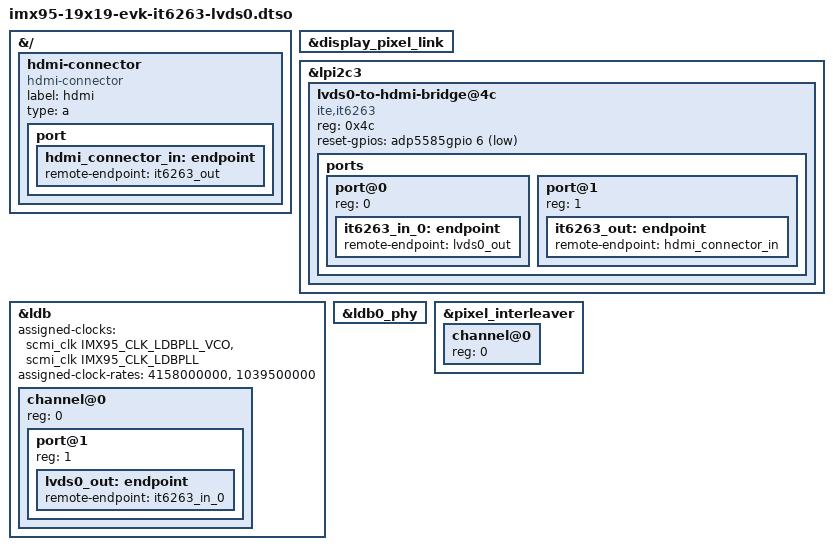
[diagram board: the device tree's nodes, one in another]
// SPDX-License-Identifier: (GPL-2.0+ OR MIT)
/*
 * Copyright 2023 NXP
 */

/dts-v1/;
/plugin/;

#include <dt-bindings/clock/fsl,imx95-clock.h>
#include <dt-bindings/gpio/gpio.h>

&{/} {
	hdmi-connector {
		compatible = "hdmi-connector";
		label = "hdmi";
		type = "a";

		port {
			hdmi_connector_in: endpoint {
				remote-endpoint = <&it6263_out>;
			};
		};
	};
};

&display_pixel_link {
	status = "okay";
};

&lpi2c3 {
	#address-cells = <1>;
	#size-cells = <0>;

	lvds0-to-hdmi-bridge@4c {
		compatible = "ite,it6263";
		reg = <0x4c>;
		reset-gpios = <&adp5585gpio 6 GPIO_ACTIVE_LOW>;

		ports {
			#address-cells = <1>;
			#size-cells = <0>;

			port@0 {
				reg = <0>;

				it6263_in_0: endpoint {
					remote-endpoint = <&lvds0_out>;
				};
			};

			port@1 {
				reg = <1>;

				it6263_out: endpoint {
					remote-endpoint = <&hdmi_connector_in>;
				};
			};
		};
	};
};


&ldb {
	#address-cells = <1>;
	#size-cells = <0>;
	assigned-clocks = <&scmi_clk IMX95_CLK_LDBPLL_VCO>,
			  <&scmi_clk IMX95_CLK_LDBPLL>;
	assigned-clock-rates = <4158000000>, <1039500000>;
	status = "okay";

	channel@0 {
		#address-cells = <1>;
		#size-cells = <0>;
		status = "okay";
		reg = <0>;

		port@1 {
			reg = <1>;

			lvds0_out: endpoint {
				remote-endpoint = <&it6263_in_0>;
			};
		};
	};
};

&ldb0_phy {
	status = "okay";
};

&pixel_interleaver {
	#address-cells = <1>;
	#size-cells = <0>;
	status = "okay";

	channel@0 {
		reg = <0>;
		status = "okay";
	};
};
